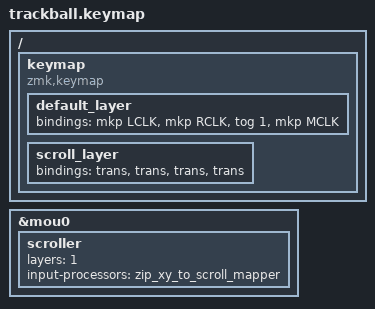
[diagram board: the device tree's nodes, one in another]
/*
 * Copyright (c) 2022 The ZMK Contributors
 *
 * SPDX-License-Identifier: MIT
 */

#include <behaviors.dtsi>
#include <behaviors/mouse_key_press.dtsi>
#include <dt-bindings/zmk/keys.h>
#include <dt-bindings/zmk/bt.h>
#include <dt-bindings/zmk/pointing.h>
#include <dt-bindings/zmk/mouse.h>
#include <dt-bindings/zmk/outputs.h>
#include <input/processors.dtsi>

/ {
    keymap {
        compatible = "zmk,keymap";
        default_layer {
            bindings = <
            &mkp LCLK &mkp RCLK &tog 1 &mkp MCLK
            >;
        };

        scroll_layer {
            bindings = <
            &trans &trans &trans &trans
            >;
        };
    };
};


&mou0 {
    scroller {
        layers = <1>;
        input-processors = <&zip_xy_to_scroll_mapper>;
    };
};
